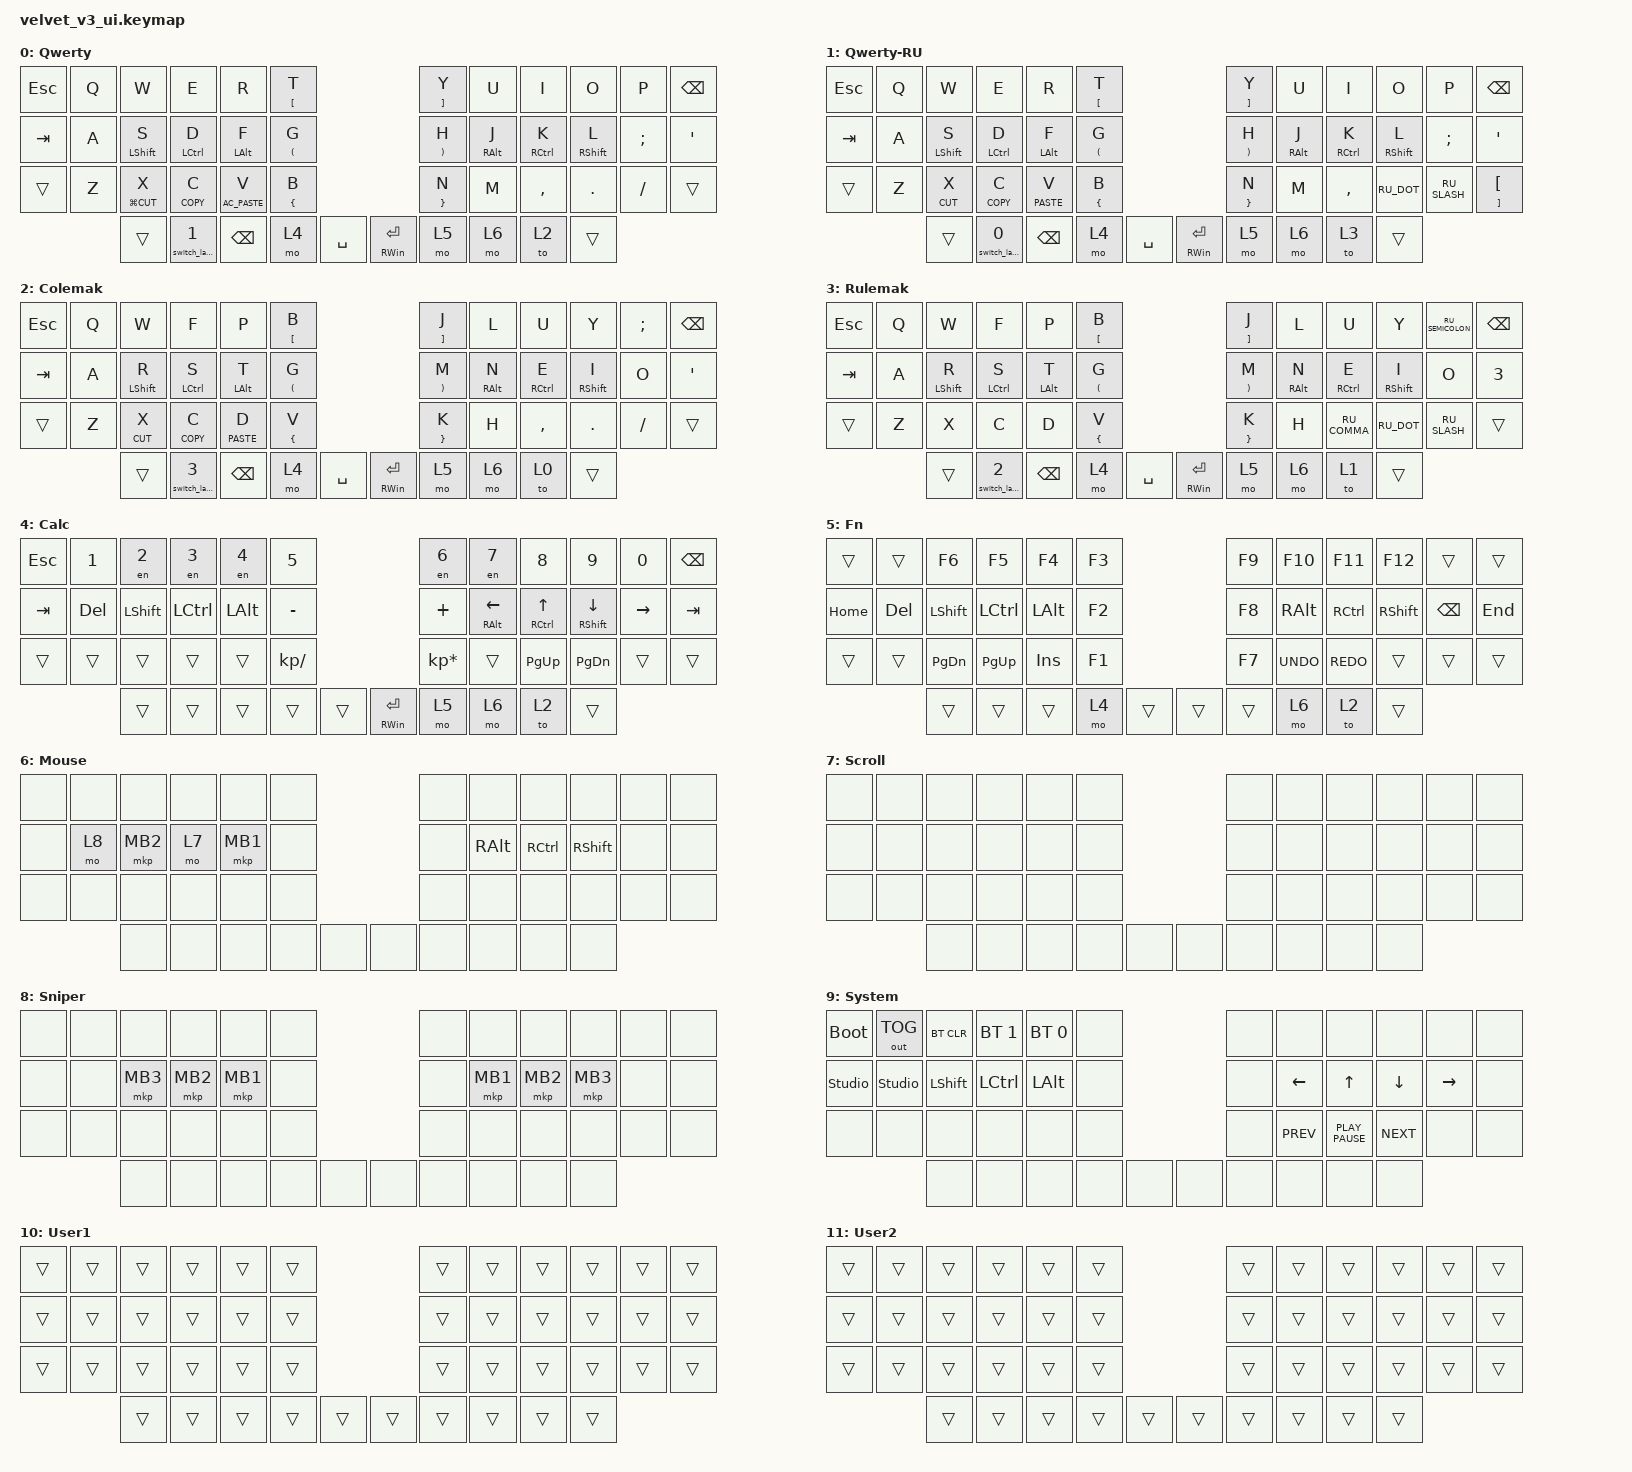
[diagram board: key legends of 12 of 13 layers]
#include "keys_ru.h"
#include <dt-bindings/zmk/input_transform.h>
#include <input/processors.dtsi>
#include <zephyr/dt-bindings/input/input-event-codes.h>
#include <behaviors.dtsi>
#include <dt-bindings/zmk/bt.h>
#include <dt-bindings/zmk/keys.h>
#include <dt-bindings/zmk/outputs.h>
#include <dt-bindings/zmk/pointing.h>

&mt {
    tapping-term-ms = <280>;
    flavor = "tap-preferred";
    require-prior-idle-ms = <150>;
    quick-tap-ms = <200>;
};

&mmv {
    acceleration-exponent = <2>;
    time-to-max-speed-ms = <400>;
};

/ {
    behaviors {
        cap_sen: cap_sen {
            compatible = "zmk,behavior-hold-tap";
            label = "CAP_SEN";
            bindings = <&mo>, <&kp>;

            #binding-cells = <2>;
            tapping-term-ms = <150>;
            hold-while-undecided;
        };
    };

    combos { compatible = "zmk,combos"; };

    macros {
        switch_lang: switch_lang {
            compatible = "zmk,behavior-macro";
            #binding-cells = <0>;
            bindings = <&kp LG(SPACE)>;
            label = "switch_lang";
        };

        switch_layer_lang: switch_layer_lang {
            compatible = "zmk,behavior-macro-one-param";
            #binding-cells = <1>;
            bindings =
                <&macro_param_1to1 &to MACRO_PLACEHOLDER>,
                <&macro_wait_time 50>,
                <&switch_lang>;

            label = "switch_layer_lang";
        };

        en: en {
            compatible = "zmk,behavior-macro-one-param";
            #binding-cells = <1>;
            bindings =
                <&switch_lang>,
                <&macro_press>,
                <&macro_param_1to1 &kp MACRO_PLACEHOLDER>,
                <&macro_pause_for_release>,
                <&macro_release>,
                <&macro_param_1to1 &kp MACRO_PLACEHOLDER &switch_lang>;

            label = "EN";
        };
    };

    keymap {
        compatible = "zmk,keymap";

        qwerty {
            bindings = <
&kp ESC  &kp Q  &kp W             &kp E                 &kp R             &mt LEFT_BRACKET T                                        &mt RIGHT_BRACKET Y      &kp U            &kp I                &kp O              &kp P      &kp BACKSPACE
&kp TAB  &kp A  &mt LEFT_SHIFT S  &mt LEFT_CONTROL D    &mt LEFT_ALT F    &mt LEFT_PARENTHESIS G                                    &mt RIGHT_PARENTHESIS H  &mt RIGHT_ALT J  &mt RIGHT_CONTROL K  &mt RIGHT_SHIFT L  &kp SEMI   &kp SINGLE_QUOTE
&trans   &kp Z  &mt LG(K_CUT) X   &mt K_COPY C          &mt C_AC_PASTE V  &mt LEFT_BRACE B                                          &mt RIGHT_BRACE N        &kp M            &kp COMMA            &kp DOT            &kp SLASH  &trans
                &trans            &switch_layer_lang 1  &kp BACKSPACE     &mo 4                   &kp SPACE    &mt RIGHT_WIN ENTER  &mo 5                    &mo 6            &to 2                &trans
            >;

            display-name = "Qwerty";
            label = "qwerty";
        };

        qwerty_ru {
            display-name = "Qwerty-RU";
            bindings = <
&kp ESC  &kp Q  &kp W             &kp E                 &kp R           &mt LEFT_BRACKET T                                        &mt RIGHT_BRACKET Y      &kp U            &kp I                &kp O              &kp P          &kp BACKSPACE
&kp TAB  &kp A  &mt LEFT_SHIFT S  &mt LEFT_CONTROL D    &mt LEFT_ALT F  &mt LEFT_PARENTHESIS G                                    &mt RIGHT_PARENTHESIS H  &mt RIGHT_ALT J  &mt RIGHT_CONTROL K  &mt RIGHT_SHIFT L  &kp SEMICOLON  &kp SINGLE_QUOTE
&trans   &kp Z  &mt K_CUT X       &mt K_COPY C          &mt K_PASTE V   &mt LEFT_BRACE B                                          &mt RIGHT_BRACE N        &kp M            &kp COMMA            &kp RU_DOT         &kp RU_SLASH   &mt RIGHT_BRACKET LEFT_BRACKET
                &trans            &switch_layer_lang 0  &kp BACKSPACE   &mo 4                   &kp SPACE    &mt RIGHT_WIN ENTER  &mo 5                    &mo 6            &to 3                &trans
            >;

            label = "qwerty_ru";
        };

        colemak {
            bindings = <
&kp ESC  &kp Q  &kp W             &kp F                 &kp P           &mt LEFT_BRACKET B                                        &mt RIGHT_BRACKET J      &kp L            &kp U                &kp Y              &kp SEMI  &kp BACKSPACE
&kp TAB  &kp A  &mt LEFT_SHIFT R  &mt LEFT_CONTROL S    &mt LEFT_ALT T  &mt LEFT_PARENTHESIS G                                    &mt RIGHT_PARENTHESIS M  &mt RIGHT_ALT N  &mt RIGHT_CONTROL E  &mt RIGHT_SHIFT I  &kp O     &kp SINGLE_QUOTE
&trans   &kp Z  &mt K_CUT X       &mt K_COPY C          &mt K_PASTE D   &mt LEFT_BRACE V                                          &mt RIGHT_BRACE K        &kp H            &kp COMMA            &kp DOT            &kp FSLH  &trans
                &trans            &switch_layer_lang 3  &kp BACKSPACE   &mo 4                   &kp SPACE    &mt RIGHT_WIN ENTER  &mo 5                    &mo 6            &to 0                &trans
            >;

            display-name = "Colemak";
            label = "colemak";
        };

        rulemak {
            display-name = "Rulemak";
            bindings = <
&kp ESC  &kp Q  &kp W             &kp F                 &kp P           &mt LEFT_BRACKET B                                        &mt RIGHT_BRACKET J      &kp L            &kp U                &kp Y              &kp RU_SEMICOLON  &kp BACKSPACE
&kp TAB  &kp A  &mt LEFT_SHIFT R  &mt LEFT_CONTROL S    &mt LEFT_ALT T  &mt LEFT_PARENTHESIS G                                    &mt RIGHT_PARENTHESIS M  &mt RIGHT_ALT N  &mt RIGHT_CONTROL E  &mt RIGHT_SHIFT I  &kp O             &kp NUMBER_3
&trans   &kp Z  &kp X             &kp C                 &kp D           &mt LEFT_BRACE V                                          &mt RIGHT_BRACE K        &kp H            &kp RU_COMMA         &kp RU_DOT         &kp RU_SLASH      &trans
                &trans            &switch_layer_lang 2  &kp BACKSPACE   &mo 4                   &kp SPACE    &mt RIGHT_WIN ENTER  &mo 5                    &mo 6            &to 1                &trans
            >;

            label = "rulemac";
        };

        calc {
            bindings = <
&kp ESCAPE  &kp N1      &en N2          &en N3            &en N4        &kp N5                                        &en N6           &en N7                    &kp N8                      &kp N9                      &kp N0           &kp BACKSPACE
&kp TAB     &kp DELETE  &kp LEFT_SHIFT  &kp LEFT_CONTROL  &kp LEFT_ALT  &kp MINUS                                     &kp PLUS         &mt RIGHT_ALT LEFT_ARROW  &mt RIGHT_CONTROL UP_ARROW  &mt RIGHT_SHIFT DOWN_ARROW  &kp RIGHT_ARROW  &kp TAB
&trans      &trans      &trans          &trans            &trans        &kp KP_DIVIDE                                 &kp KP_MULTIPLY  &trans                    &kp PAGE_UP                 &kp PAGE_DOWN               &trans           &trans
                        &trans          &trans            &trans        &trans         &trans    &mt RIGHT_WIN ENTER  &mo 5            &mo 6                     &to 2                       &trans
            >;

            display-name = "Calc";
            label = "calc";
        };

        fn {
            bindings = <
&trans    &trans      &kp F6          &kp F5            &kp F4        &kp F3                    &kp F9  &kp F10        &kp F11            &kp F12          &trans         &trans
&kp HOME  &kp DELETE  &kp LEFT_SHIFT  &kp LEFT_CONTROL  &kp LEFT_ALT  &kp F2                    &kp F8  &kp RIGHT_ALT  &kp RIGHT_CONTROL  &kp RIGHT_SHIFT  &kp BACKSPACE  &kp END
&trans    &trans      &kp PAGE_DOWN   &kp PAGE_UP       &kp INSERT    &kp F1                    &kp F7  &kp K_UNDO     &kp K_REDO         &trans           &trans         &trans
                      &trans          &trans            &trans        &mo 4   &trans    &trans  &trans  &mo 6          &to 2              &trans
            >;

            display-name = "Fn";
        };

        mouse {
            bindings = <
&none  &none  &none     &none  &none     &none                  &none  &none          &none              &none            &none  &none
&none  &mo 8  &mkp MB2  &mo 7  &mkp MB1  &none                  &none  &kp RIGHT_ALT  &kp RIGHT_CONTROL  &kp RIGHT_SHIFT  &none  &none
&none  &none  &none     &none  &none     &none                  &none  &none          &none              &none            &none  &none
              &none     &none  &none     &none  &none    &none  &none  &none          &none              &none
            >;

            display-name = "Mouse";
        };

        scroll {
            bindings = <
&none  &none  &none  &none  &none  &none                  &none  &none  &none  &none  &none  &none
&none  &none  &none  &none  &none  &none                  &none  &none  &none  &none  &none  &none
&none  &none  &none  &none  &none  &none                  &none  &none  &none  &none  &none  &none
              &none  &none  &none  &none  &none    &none  &none  &none  &none  &none
            >;

            display-name = "Scroll";
        };

        sniper {
            bindings = <
&none  &none  &none     &none     &none     &none                  &none  &none     &none     &none     &none  &none
&none  &none  &mkp MB3  &mkp MB2  &mkp MB1  &none                  &none  &mkp MB1  &mkp MB2  &mkp MB3  &none  &none
&none  &none  &none     &none     &none     &none                  &none  &none     &none     &none     &none  &none
              &none     &none     &none     &none  &none    &none  &none  &none     &none     &none
            >;

            display-name = "Sniper";
        };

        sys {
            bindings = <
&bootloader     &out OUT_TOG    &bt BT_CLR      &bt BT_SEL 1      &bt BT_SEL 0  &none                  &none  &none       &none             &none           &none      &none
&studio_unlock  &studio_unlock  &kp LEFT_SHIFT  &kp LEFT_CONTROL  &kp LEFT_ALT  &none                  &none  &kp LEFT    &kp UP            &kp DOWN_ARROW  &kp RIGHT  &none
&none           &none           &none           &none             &none         &none                  &none  &kp K_PREV  &kp K_PLAY_PAUSE  &kp K_NEXT      &none      &none
                                &none           &none             &none         &none  &none    &none  &none  &none       &none             &none
            >;

            display-name = "System";
        };

        User1 {
            bindings = <
&trans  &trans  &trans  &trans  &trans  &trans                    &trans  &trans  &trans  &trans  &trans  &trans
&trans  &trans  &trans  &trans  &trans  &trans                    &trans  &trans  &trans  &trans  &trans  &trans
&trans  &trans  &trans  &trans  &trans  &trans                    &trans  &trans  &trans  &trans  &trans  &trans
                &trans  &trans  &trans  &trans  &trans    &trans  &trans  &trans  &trans  &trans
            >;

            display-name = "User1";
        };

        User2 {
            bindings = <
&trans  &trans  &trans  &trans  &trans  &trans                    &trans  &trans  &trans  &trans  &trans  &trans
&trans  &trans  &trans  &trans  &trans  &trans                    &trans  &trans  &trans  &trans  &trans  &trans
&trans  &trans  &trans  &trans  &trans  &trans                    &trans  &trans  &trans  &trans  &trans  &trans
                &trans  &trans  &trans  &trans  &trans    &trans  &trans  &trans  &trans  &trans
            >;

            display-name = "User2";
        };

        User3 {
            bindings = <
&trans  &trans  &trans  &trans  &trans  &trans                    &trans  &trans  &trans  &trans  &trans  &trans
&trans  &trans  &trans  &trans  &trans  &trans                    &trans  &trans  &trans  &trans  &trans  &trans
&trans  &trans  &trans  &trans  &trans  &trans                    &trans  &trans  &trans  &trans  &trans  &trans
                &trans  &trans  &trans  &trans  &trans    &trans  &trans  &trans  &trans  &trans
            >;

            display-name = "User3";
        };
    };

    conditional_layers {
        compatible = "zmk,conditional-layers";

        cond_sys {
            if-layers = <4 5>;
            then-layer = <9>;
        };
    };
};

&trackball { cpi = <1200>; };

&trackball_listener {
    input-processors = <&zip_xy_scaler 9 20>;

    scroller {
        layers = <7>;
        input-processors =
            <&zip_xy_transform INPUT_TRANSFORM_Y_INVERT>,
            <&zip_xy_scaler 8 32>,
            <&zip_xy_to_scroll_mapper>;
    };

    sniper {
        layers = <8>;
        input-processors = <&zip_xy_scaler 1 4>;
    };
};
